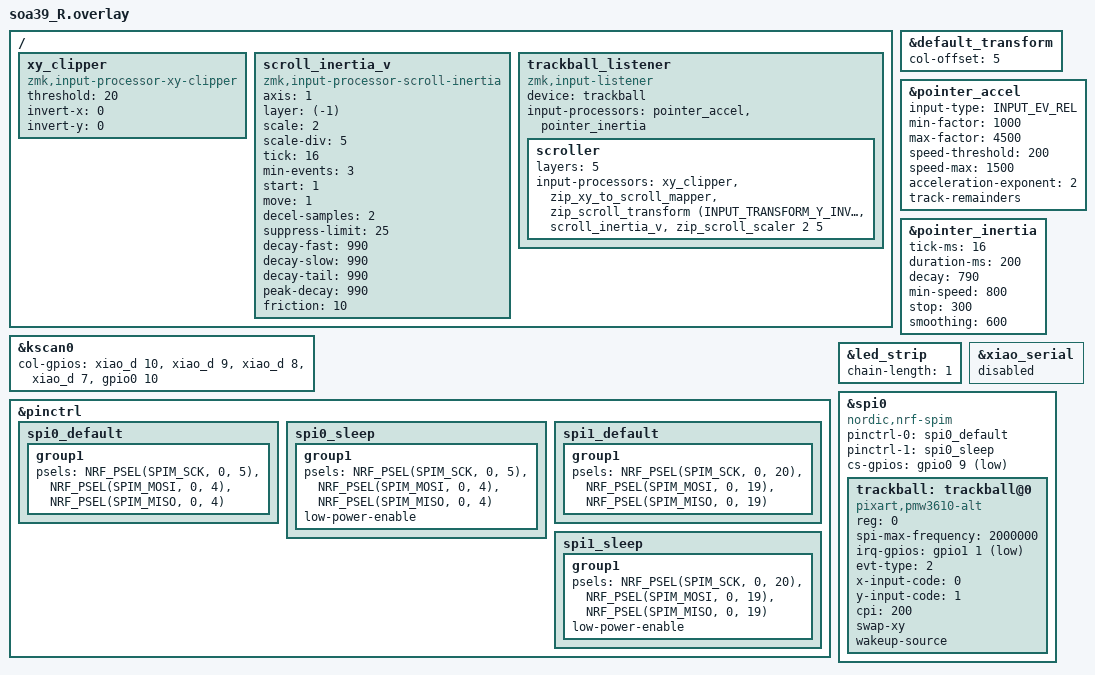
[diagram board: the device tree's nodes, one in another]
#include "soa39.dtsi"
#include <dt-bindings/zmk/input_transform.h>
#include <dt-bindings/input/input-event-codes.h>
#include <input/processors.dtsi>
#include <behaviors/input_gestures_accel.dtsi>
#include <behaviors/input_pointer_inertia.dtsi>

&default_transform {
    col-offset = <5>;
};

&kscan0 {
        col-gpios
            = <&xiao_d 10 GPIO_ACTIVE_HIGH>
            , <&xiao_d 9 GPIO_ACTIVE_HIGH>
            , <&xiao_d 8 GPIO_ACTIVE_HIGH>
            , <&xiao_d 7 GPIO_ACTIVE_HIGH>
            , <&gpio0 10 GPIO_ACTIVE_HIGH>
            ;
};

// カーソル加速 (oleksandrmaslov/zmk-pointing-acceleration)
// ボールをゆっくり回した時は素の CPI=200 で精密に、速く弾いた時だけ
// 倍率を上げて一気に飛ばす。スクロールレイヤ(5)には掛からない
// (下の scroller 子ノードがマッチすると base の input-processors はスキップされるため)。
//
// 速度の目安 (CPI=200 / レポート間隔 16ms=62.5Hz、軸ごとに独立計算):
//   cps(counts/sec) = |1レポートの移動量| x 62.5 ≒ 200 x 物理速度[inch/s]
//     1.0 inch/s -> cps  200
//     5.0 inch/s -> cps 1000
//     7.5 inch/s -> cps 1500
//
// 実効CPI: ~1.0 in/s=200 / 2.5 in/s=248 / 5.0 in/s=532 / 7.5 in/s~=900
&pointer_accel {
    input-type = <INPUT_EV_REL>;

    // 低速側は等倍 (CPI が既に下限近い 200 なのでこれ以上減速させない)
    min-factor = <1000>;          // 1.000x
    // 高速側の最大倍率。実効 200 x 4.5 = 900 CPI 相当。
    // CPI を 400->200 に半減させた分、到達点を保つため倍率は上げてある
    // (体感の「加速の効き」は 400x3.5=1400 相当から 900 相当へ弱まる)
    max-factor = <4500>;          // 4.500x

    // ここ以下は等倍のまま = 精密操作域 (~1.0 inch/s)
    speed-threshold = <200>;
    // ここで max-factor に到達 (~7.5 inch/s)
    speed-max = <1500>;

    // 2 = 二次カーブ。閾値直後は緩やかに効き、速度が乗ってから一気に伸びる
    // (1=リニアだと中速域が過敏になりやすい)
    acceleration-exponent = <2>;

    // 端数(1未満の移動量)を蓄積して次レポートに繰り越す。
    // 低 CPI では切り捨て損失が効くので必須
    track-remainders;
};

// カーソル慣性 (このリポジトリ内の自作プロセッサ / src/input_processor_pointer_inertia.c)
// 速く動かして止めた直後だけ、約0.2秒カーソルを滑らせる。
// &pointer_accel より後ろに置くこと (加速後の速度で滑らせないと
// 手を離した瞬間に急減速して見えるため)。
&pointer_inertia {
    tick-ms = <16>;        // センサーのレポート間隔と一致させる
    duration-ms = <200>;   // 滑る時間の上限 = 要望の 0.2 秒
    decay = <790>;         // 16ms x 12.5tick で初速の約5%まで減衰
    min-speed = <800>;     // 加速後 800counts/sec (生 ~3 inch/s) 未満では発動しない
    stop = <300>;          // 0.3カウント/tick を下回ったら終了
    smoothing = <600>;     // 速度推定EMAの新サンプル重み
};

/ {
    xy_clipper: xy_clipper {
        compatible = "zmk,input-processor-xy-clipper";
        #input-processor-cells = <0>;
        threshold = <20>;
        invert-x = <0>;
        invert-y = <0>;
    };

    // iOS風 慣性スクロール (mjmjm0101/zmk-input-processor-scroll-inertia)
    // 縦(Y)のみ。SCROLLレイヤー(5)専用。scale/scale-div は下流の
    // zip_scroll_scaler 2 5 に合わせる (慣性出力と実スクロールの整合)。
    scroll_inertia_v: scroll_inertia_v {
        compatible = "zmk,input-processor-scroll-inertia";
        #input-processor-cells = <0>;
        axis = <1>;       // 0=両軸, 1=Y(縦)のみ, 2=X(横)のみ
        // layer=-1: 層ゲート/層リセットを無効化。&mo 5(モメンタリ)は
        // フリック直後にキーを離す→層5 OFF で惰性が即殺されるため。
        // コースト出力は入力チェーンを通さず直接HIDで送るので、層を
        // 抜けた後も惰性が継続する(stop/減衰/gesture-timeout で自然終了)。
        layer = <(-1)>;
        scale = <2>;      // 下流 zip_scroll_scaler 2 5 に合わせる
        scale-div = <5>;

        // --- 62.5Hz(16ms)/CPI600 向けチューニング ---
        // NOTE: CPI は 400 に変更済み。下の閾値は CPI600 前提なので、
        //       診断用の強制発動を解除する際は start/move を再調整すること。
        // 既定は 1000CPI/125Hz(8ms)前提。作者の 125Hz→250Hz 値の振り方を
        // 62.5Hz へ外挿(レート半分: tick倍/min-events半分/friction倍/decay→より減衰)。
        tick = <16>;           // 62.5Hz = 16ms (既定8=125Hz)
        // === 診断用: 強制発動テスト ===
        // どんなスクロールでも必ず arm させ、慣性パイプラインが生きているか確認する。
        // 惰性が出れば(暴走気味でも)閾値調整だけの問題。出なければ構造問題→ログ調査へ。
        min-events = <3>;      // ほぼ即 arm 許可
        start = <1>;           // 事実上どんな速度でも発動
        move = <1>;            // 事実上どんな移動でも発動
        decel-samples = <2>;
        suppress-limit = <25>;
        decay-fast = <990>;    // 減衰ゆるめ=惰性を長く=見えやすく
        decay-slow = <990>;
        decay-tail = <990>;
        peak-decay = <990>;
        friction = <10>;       // 摩擦弱め=惰性を長く=見えやすく
    };

    trackball_listener {
        status = "okay";
        compatible = "zmk,input-listener";
        device = <&trackball>;
        // Auto mouse layer: トラックボール操作時にレイヤを 700ms 一時 active 化
        // 数字はレイヤ index (例: 2 = MOUSE レイヤ)
        // input-processors = <&zip_temp_layer 2 700>;

        // カーソル移動時の加速 + 慣性。scroller (layer 5) がマッチしている間は
        // この base 側はスキップされるので、スクロールには影響しない。
        // 順序重要: 慣性は加速後の速度を見る必要がある
        input-processors = <&pointer_accel>, <&pointer_inertia>;

        scroller {
            layers = <5>;
            input-processors =
                <&xy_clipper>,
                <&zip_xy_to_scroll_mapper>,
                <&zip_scroll_transform (INPUT_TRANSFORM_Y_INVERT)>,
                <&scroll_inertia_v>,
                <&zip_scroll_scaler 2 5>;
        };
    };
};

&pinctrl {
    spi0_default: spi0_default {
        group1 {
            psels = <NRF_PSEL(SPIM_SCK, 0, 5)>,
                <NRF_PSEL(SPIM_MOSI, 0, 4)>,
                <NRF_PSEL(SPIM_MISO, 0, 4)>;
        };
    };

    spi0_sleep: spi0_sleep {
        group1 {
            psels = <NRF_PSEL(SPIM_SCK, 0, 5)>,
                <NRF_PSEL(SPIM_MOSI, 0, 4)>,
                <NRF_PSEL(SPIM_MISO, 0, 4)>;
            low-power-enable;
        };
    };

    spi1_default: spi1_default {
        group1 {
            psels = <NRF_PSEL(SPIM_SCK, 0, 20)>,
                <NRF_PSEL(SPIM_MOSI, 0, 19)>,
                <NRF_PSEL(SPIM_MISO, 0, 19)>;
        };
    };

    spi1_sleep: spi1_sleep {
        group1 {
            psels = <NRF_PSEL(SPIM_SCK, 0, 20)>,
                <NRF_PSEL(SPIM_MOSI, 0, 19)>,
                <NRF_PSEL(SPIM_MISO, 0, 19)>;
            low-power-enable;
        };
    };
};

// Override led_strip to set red color for right side  
&led_strip {
    status = "okay";
    chain-length = <1>;
    // Pre-set WS2812 to red color (0xFF0000) for right side identification
};

&xiao_serial { status = "disabled"; };

&spi0 {
    status = "okay";
    compatible = "nordic,nrf-spim";
    pinctrl-0 = <&spi0_default>;
    pinctrl-1 = <&spi0_sleep>;
    pinctrl-names = "default", "sleep";
    cs-gpios = <&gpio0 9 GPIO_ACTIVE_LOW>;

    trackball: trackball@0 {
        status = "okay";
        compatible = "pixart,pmw3610-alt";
        reg = <0>;
        spi-max-frequency = <2000000>;
        irq-gpios = <&gpio1 1 (GPIO_ACTIVE_LOW | GPIO_PULL_UP)>;
        evt-type = <2>;  // INPUT_EV_REL
        x-input-code = <0>;  // INPUT_REL_X
        y-input-code = <1>;  // INPUT_REL_Y
        // 感度。範囲200-3200/200刻み (300 のような中間値は設定不可)。
        // 200 = センサーの下限。低速時の精度を最優先し、
        // 速い時の飛びは &pointer_accel (最大4.5x) で補う
        cpi = <200>;
        swap-xy;
        // force-awake 削除: idle/active切替のたびに PERFORMANCE レジスタが
        // 書き換わり、それがカーソルジッター(モード変化時のブレ)のトリガーに
        // なっていたため。ハード側の RUN/REST 自動ダウンシフトに任せる方が
        // 省電力にも有利。
        wakeup-source;
    };
};

